# BS2X register map
File version: 0.1
CPU: other r0p0, little endian, MPU, FPU, 3 interrupt priority bits
Registers are 32-bit, read-write, reset 0x0 unless marked. A register's access mark holds for its fields unless they carry their own. Offsets are from the block's base; [hi:lo] are bit positions; {n}, {i} and the like mark numbered series.

## DMA — DMA controller with 4 channels
Base 0x52070000
Same registers: SDMA 0x520A0000
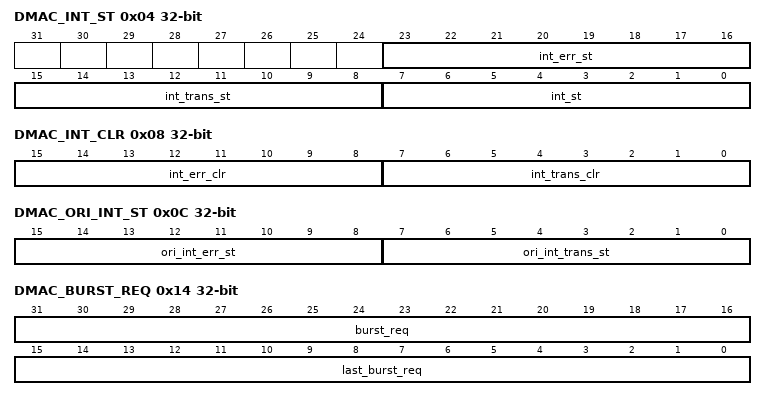
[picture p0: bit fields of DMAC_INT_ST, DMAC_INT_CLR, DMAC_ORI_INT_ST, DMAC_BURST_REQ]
0x04 DMAC_INT_ST — Interrupt status register
  [23:16] int_err_st ro — Channel error interrupt status (after mask)
  [15:8] int_trans_st ro — Channel transfer interrupt status (after mask)
  [7:0] int_st ro — Channel interrupt status (after mask)
0x08 DMAC_INT_CLR — Interrupt clear register
  [15:8] int_err_clr — Clear channel error interrupt
  [7:0] int_trans_clr — Clear channel transfer interrupt
0x0C DMAC_ORI_INT_ST — Raw interrupt status register
  [15:8] ori_int_err_st ro — Raw error interrupt status (before mask)
  [7:0] ori_int_trans_st ro — Raw transfer interrupt status (before mask)
0x10 DMAC_EN_CHNS — Channel enable query register
  [7:0] en_chns ro — Channel enable status: 0=disabled; 1=enabled
0x14 DMAC_BURST_REQ — Burst software request register
  [31:16] burst_req — Burst request per peripheral
  [15:0] last_burst_req — Last burst request per peripheral
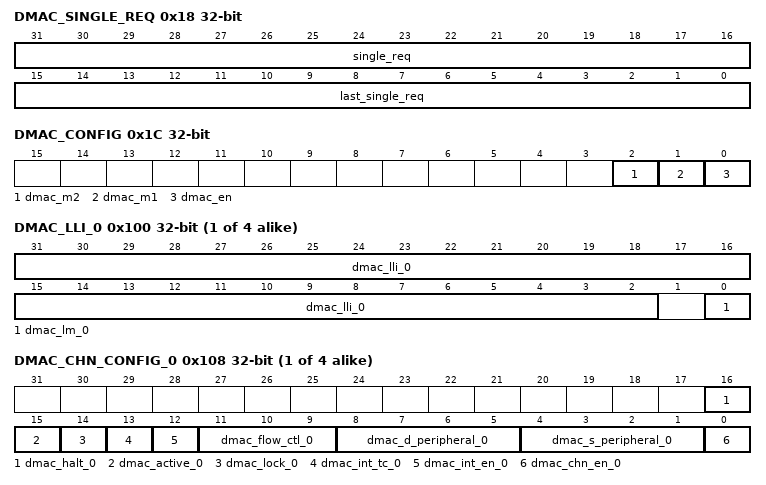
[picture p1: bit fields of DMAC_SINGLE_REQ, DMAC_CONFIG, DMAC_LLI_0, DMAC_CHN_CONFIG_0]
0x18 DMAC_SINGLE_REQ — Single software request register
  [31:16] single_req — Single request per peripheral
  [15:0] last_single_req — Last single request per peripheral
0x1C DMAC_CONFIG — DMA configuration register
  [2] dmac_m2 — Master 2 endianness: 0=little; 1=big
  [1] dmac_m1 — Master 1 endianness: 0=little; 1=big
  [0] dmac_en — DMAC enable: 0=disabled; 1=enabled
0x20 DMAC_SYNC — DMA sync register
  [15:0] damc_sync — DMA request sync: 0=enable sync; 1=disable sync
{0x100+0x20*i} DMAC_LLI_{i} (i=0..3) — Channel {i} [dim=4] linked list register
  [31:2] dmac_lli_0 — Linked list address [31:2]
  [0] dmac_lm_0 — Master for next LLI node: 0=Master1; 1=Master2
{0x104+0x20*i} DMAC_D_ADDR_{i} (i=0..3) — Channel {i} [dim=4] destination address
  [31:0] dmac_d_addr_0 — Channel 0 destination address
{0x108+0x20*i} DMAC_CHN_CONFIG_{i} (i=0..3) — Channel {i} [dim=4] configuration register
  [16] dmac_halt_0 — Halt: 0=allow DMA; 1=ignore DMA requests
  [15] dmac_active_0 ro — FIFO has data: 0=no; 1=yes
  [14] dmac_lock_0 — Bus lock: 0=disabled; 1=enabled
  [13] dmac_int_tc_0 — Transfer complete interrupt mask: 0=masked; 1=unmasked
  [12] dmac_int_en_0 — Error interrupt mask: 0=masked; 1=unmasked
  [11:9] dmac_flow_ctl_0 — Flow control: 000=mem2mem; 001=mem2per; 010=per2mem; 011=per2per(DMAC); 100=per2per(dst); 101=mem2per(dst); 110=per2mem(src); 111=per2per(src)
    0=Mem2Mem_DMAC (Memory to Memory, DMAC flow control); 1=Mem2Per_DMAC (Memory to Peripheral, DMAC flow control); 2=Per2Mem_DMAC (Peripheral to Memory, DMAC flow control); 3=Per2Per_DMAC (Peripheral to Peripheral, DMAC flow control); 4=Per2Per_Dst (Peripheral to Peripheral, Destination flow control); 5=Mem2Per_Dst (Memory to Peripheral, Destination flow control); 6=Per2Mem_Src (Peripheral to Memory, Source flow control); 7=Per2Per_Src (Peripheral to Peripheral, Source flow control)
  [8:5] dmac_d_peripheral_0 — Destination peripheral select
  [4:1] dmac_s_peripheral_0 — Source peripheral select
  [0] dmac_chn_en_0 — Channel enable: 0=disable; 1=enable
{0x110+0x20*i} DMAC_S_ADDR_{i} (i=0..3) — Channel {i} [dim=4] source address
  [31:0] dmac_s_addr_0 — Channel 0 source address
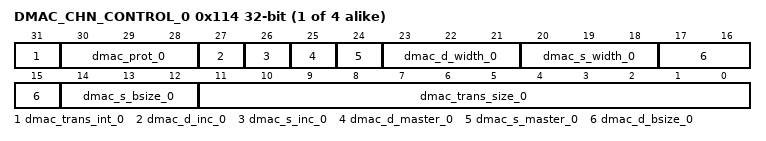
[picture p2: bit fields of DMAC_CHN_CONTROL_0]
{0x114+0x20*i} DMAC_CHN_CONTROL_{i} (i=0..3) — Channel {i} [dim=4] control register
  [31] dmac_trans_int_0 — Transfer complete interrupt enable
  [30:28] dmac_prot_0 — Protection HPROT[2:0]
  [27] dmac_d_inc_0 — Destination address increment
  [26] dmac_s_inc_0 — Source address increment: 0=no; 1=yes
  [25] dmac_d_master_0 — Destination master
  [24] dmac_s_master_0 — Source master: 0=Master1; 1=Master2
  [23:21] dmac_d_width_0 — Destination width
    0=Byte (8-bit); 1=Halfword (16-bit); 2=Word (32-bit)
  [20:18] dmac_s_width_0 — Source width: 000=8bit; 001=16bit; 010=32bit
    0=Byte (8-bit); 1=Halfword (16-bit); 2=Word (32-bit)
  [17:15] dmac_d_bsize_0 — Destination burst size
  [14:12] dmac_s_bsize_0 — Source burst size: 000=1; 001=4; 010=8; 011=16; 100=32; 101=64; 110=128; 111=256
    0=BS1 (Burst size 1); 1=BS4 (Burst size 4); 2=BS8 (Burst size 8); 3=BS16 (Burst size 16); 4=BS32 (Burst size 32); 5=BS64 (Burst size 64); 6=BS128 (Burst size 128); 7=BS256 (Burst size 256)
  [11:0] dmac_trans_size_0 — Transfer size
